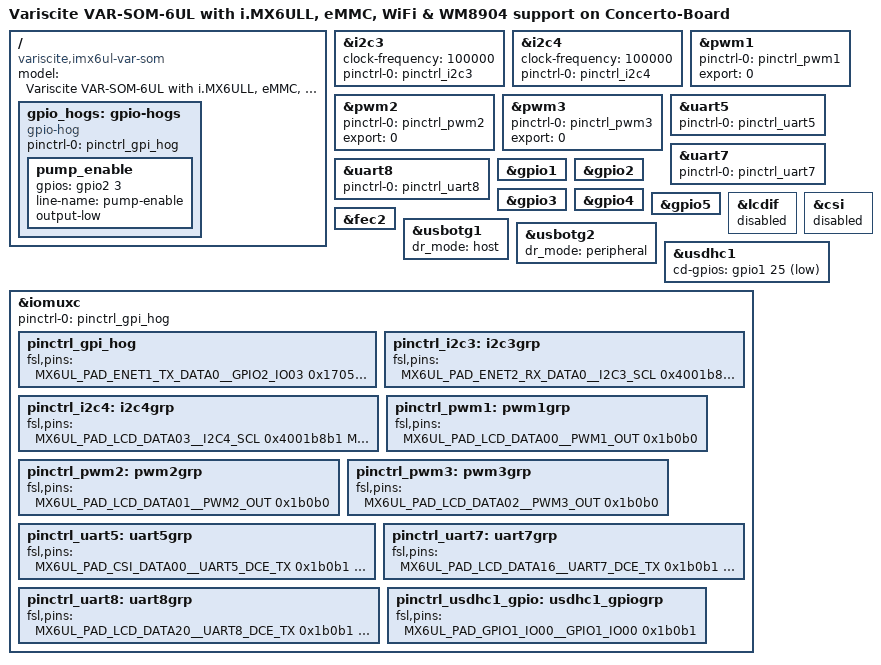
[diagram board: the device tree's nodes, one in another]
/dts-v1/;


#include "imx6ull.dtsi"
#include "imx6ull-var-som.dtsi"
#include "imx6ul-imx6ull-var-som-emmc.dtsi"
#include "imx6ul-imx6ull-var-som-wifi.dtsi"
#include "imx6ul-imx6ull-var-dart-wm8731.dtsi"
#include "imx6ull-var-som-concerto-board.dtsi"

/ {
  model = "Variscite VAR-SOM-6UL with i.MX6ULL, eMMC, WiFi & WM8904 support on Concerto-Board";
  compatible = "variscite,imx6ul-var-som", "fsl,imx6ull";


  gpio_hogs: gpio-hogs {
      compatible = "gpio-hog";
      pinctrl-names = "default";
      pinctrl-0 = <&pinctrl_gpi_hog>;

      pump_enable {
          gpios = <&gpio2 3 GPIO_ACTIVE_HIGH>; /* GPIO2_IO03, Active High */
          line-name = "pump-enable";
          output-low; /* Set initial state to low */
      };
  };

};


/* I2C3 */
&i2c3 {
    clock-frequency = <100000>;
    pinctrl-names = "default";
    pinctrl-0 = <&pinctrl_i2c3>;
    status = "okay";
};

/* I2C4 */
&i2c4 {
    clock-frequency = <100000>;
    pinctrl-names = "default";
    pinctrl-0 = <&pinctrl_i2c4>;
    status = "okay";
};

/* PWM1 */
&pwm1 {
    pinctrl-names = "default";
    pinctrl-0 = <&pinctrl_pwm1>;
    status = "okay";
    export = <0>;
};

/* PWM2 */
&pwm2 {
    pinctrl-names = "default";
    pinctrl-0 = <&pinctrl_pwm2>;
    status = "okay";
    export = <0>;
};
/* PWM3 */
&pwm3 {
    pinctrl-names = "default";
    pinctrl-0 = <&pinctrl_pwm3>;
    status = "okay";
    export = <0>;
};

/* ttymxc4 UART */
&uart5 {
  pinctrl-names = "default";
  pinctrl-0 = <&pinctrl_uart5>;
  status = "okay";
};

/* UART7 */
&uart7 {
    pinctrl-names = "default";
    pinctrl-0 = <&pinctrl_uart7>;
    status = "okay";
};

/* UART8 */
&uart8 {
    pinctrl-names = "default";
    pinctrl-0 = <&pinctrl_uart8>;
    status = "okay";
};

&gpio1 {
    status = "okay";
};

&gpio2 {  
    status = "okay";
};

&gpio3 {
    status = "okay";
};

&gpio4 {
    status = "okay";
};

&gpio5 {
    status = "okay";
};

&lcdif {
  status = "disabled";
};

&csi {
        status = "disabled";
};

&fec2 {
  status = "okay";
};

&usbotg1 {
    dr_mode = "host";  // Set the USB OTG controller to Host mode
    status = "okay";
};
&usbotg2 {
    dr_mode = "peripheral";  // Set the USB OTG2 to peripheral mode
    status = "okay";
};


&usdhc1 {
  cd-gpios = <&gpio1 25 GPIO_ACTIVE_LOW>;
};


&iomuxc {

  pinctrl-names = "default";
  pinctrl-0 = <&pinctrl_gpi_hog>;
  pinctrl_gpi_hog: pinctrl_gpi_hog {
      fsl,pins = <
          MX6UL_PAD_ENET1_TX_DATA0__GPIO2_IO03     0x17059  // PUMP_MICROEN_3v3
          MX6UL_PAD_ENET1_TX_CLK__GPIO2_IO06       0x17059   // PUMP_TEMPOK_3v3
          MX6UL_PAD_LCD_ENABLE__GPIO3_IO01         0x17059  // USBH_PWREN
          MX6UL_PAD_SNVS_TAMPER8__GPIO5_IO08       0x17059  // USBH_FAULT
          MX6UL_PAD_LCD_DATA11__GPIO3_IO16         0x17059  // VALVE_PWR_EN1
          MX6UL_PAD_NAND_CLE__GPIO4_IO15           0x17059  // VALVE_PWR_EN2
          MX6UL_PAD_GPIO1_IO00__GPIO1_IO00         0x17059  // VALVE_PWR_EN3
          MX6UL_PAD_SNVS_TAMPER3__GPIO5_IO03       0x17059  // VALVE_PWR_EN4
          MX6UL_PAD_LCD_DATA15__GPIO3_IO20         0x17059  // GPIO0
          MX6UL_PAD_LCD_DATA18__GPIO3_IO23         0x17059  // GPIO1
          MX6UL_PAD_LCD_DATA19__GPIO3_IO24         0x17059  // GPIO2
          MX6UL_PAD_LCD_DATA22__GPIO3_IO27         0x17059  // GPIO3
          MX6UL_PAD_LCD_DATA23__GPIO3_IO28         0x17059  // GPIO4
          MX6UL_PAD_LCD_DATA08__GPIO3_IO13         0x17059  // GPIO5
          MX6UL_PAD_LCD_DATA09__GPIO3_IO14         0x17059  // GPIO6
          MX6UL_PAD_LCD_RESET__GPIO3_IO04          0x17059  // GPIO7
          MX6UL_PAD_LCD_CLK__GPIO3_IO00            0x17059  // GPIO8
          MX6UL_PAD_ENET1_RX_EN__GPIO2_IO02        0x17059  // GPIO9
          MX6UL_PAD_SNVS_TAMPER1__GPIO5_IO01       0x17059  // TSCOM_GPIO1
          MX6UL_PAD_NAND_CE1_B__GPIO4_IO14         0x17059  // TSCOM_GPIO2
          MX6UL_PAD_SNVS_TAMPER9__GPIO5_IO09       0x17059  // TSPGM N Reset
          MX6UL_PAD_SNVS_TAMPER5__GPIO5_IO05       0x17059  // TSPGM SWCLK
          MX6UL_PAD_ENET1_TX_EN__GPIO2_IO05       0x17059  // Power Switch
          MX6UL_PAD_ENET1_RX_ER__GPIO2_IO07       0x17059  // Button Volume Down
          MX6UL_PAD_ENET1_RX_DATA1__GPIO2_IO01    0x17059  // Button Mute
          MX6UL_PAD_ENET1_RX_DATA0__GPIO2_IO00    0x17059  // Button Volume up
          MX6UL_PAD_LCD_HSYNC__GPIO3_IO02         0x17059  // Fan 1 Tach
          MX6UL_PAD_LCD_VSYNC__GPIO3_IO03         0x17059  // Fan 2 Tach
          MX6UL_PAD_NAND_DQS__GPIO4_IO16          0x17059  //VIBR_TRIG
          
      >;
  };


  /* I2C3 Pins */
  pinctrl_i2c3: i2c3grp {
      fsl,pins = <
          MX6UL_PAD_ENET2_RX_DATA0__I2C3_SCL       0x4001b8b1
          MX6UL_PAD_ENET2_RX_DATA1__I2C3_SDA       0x4001b8b1
      >;
  };

  /* I2C4 Pins */
  pinctrl_i2c4: i2c4grp {
      fsl,pins = <
          MX6UL_PAD_LCD_DATA03__I2C4_SCL          0x4001b8b1
          MX6UL_PAD_LCD_DATA02__I2C4_SDA          0x4001b8b1
      >;
  };

  /* PWM1 Pin */
  pinctrl_pwm1: pwm1grp {
      fsl,pins = <
          MX6UL_PAD_LCD_DATA00__PWM1_OUT          0x1b0b0
      >;
  };

  /* PWM2 Pin */
  pinctrl_pwm2: pwm2grp {
      fsl,pins = <
          MX6UL_PAD_LCD_DATA01__PWM2_OUT          0x1b0b0
      >;
  };

  /* PWM3 Pin */
  pinctrl_pwm3: pwm3grp {
      fsl,pins = <
          MX6UL_PAD_LCD_DATA02__PWM3_OUT          0x1b0b0
      >;
  };

  pinctrl_uart5: uart5grp {
    fsl,pins = <
      MX6UL_PAD_CSI_DATA00__UART5_DCE_TX  0x1b0b1
      MX6UL_PAD_CSI_DATA01__UART5_DCE_RX  0x1b0b1
    >;
  };

  /* UART7 Pins */
  pinctrl_uart7: uart7grp {
      fsl,pins = <
          MX6UL_PAD_LCD_DATA16__UART7_DCE_TX      0x1b0b1
          MX6UL_PAD_LCD_DATA17__UART7_DCE_RX      0x1b0b1
      >;
  };

  /* UART8 Pins */
  pinctrl_uart8: uart8grp {
      fsl,pins = <
          MX6UL_PAD_LCD_DATA20__UART8_DCE_TX      0x1b0b1
          MX6UL_PAD_LCD_DATA21__UART8_DCE_RX      0x1b0b1
      >;
  };

  pinctrl_usdhc1_gpio: usdhc1_gpiogrp {
    fsl,pins = <
      MX6UL_PAD_GPIO1_IO00__GPIO1_IO00  0x1b0b1 /* CD */
    >;
  };

};

